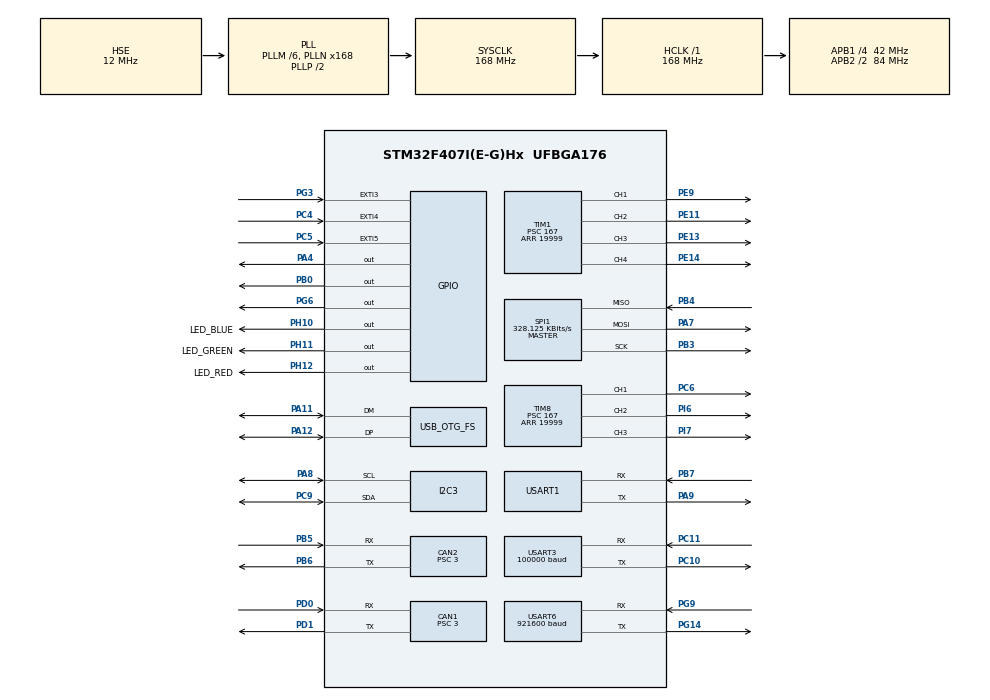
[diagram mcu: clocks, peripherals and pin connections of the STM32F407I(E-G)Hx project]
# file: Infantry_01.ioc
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CAN1.ABOM=ENABLE
CAN1.BS1=CAN_BS1_10TQ
CAN1.BS2=CAN_BS2_3TQ
CAN1.CalculateBaudRate=1000000
CAN1.CalculateTimeBit=1000
CAN1.CalculateTimeQuantum=71.42857142857143
CAN1.Prescaler=3
CAN2.ABOM=ENABLE
CAN2.BS1=CAN_BS1_10TQ
CAN2.BS2=CAN_BS2_3TQ
CAN2.CalculateBaudRate=1000000
CAN2.CalculateTimeBit=1000
CAN2.CalculateTimeQuantum=71.42857142857143
CAN2.Prescaler=3
Dma.Request0=USART1_RX
Dma.Request1=USART1_TX
Dma.Request2=USART3_RX
Dma.Request3=SPI1_RX
Dma.Request4=SPI1_TX
Dma.Request5=USART6_RX
Dma.SPI1_RX.3.Direction=DMA_PERIPH_TO_MEMORY
Dma.SPI1_RX.3.FIFOMode=DMA_FIFOMODE_DISABLE
Dma.SPI1_RX.3.Instance=DMA2_Stream0
Dma.SPI1_RX.3.MemDataAlignment=DMA_MDATAALIGN_BYTE
Dma.SPI1_RX.3.MemInc=DMA_MINC_ENABLE
Dma.SPI1_RX.3.Mode=DMA_NORMAL
Dma.SPI1_RX.3.PeriphDataAlignment=DMA_PDATAALIGN_BYTE
Dma.SPI1_RX.3.PeriphInc=DMA_PINC_DISABLE
Dma.SPI1_RX.3.Priority=DMA_PRIORITY_LOW
Dma.SPI1_TX.4.Direction=DMA_MEMORY_TO_PERIPH
Dma.SPI1_TX.4.FIFOMode=DMA_FIFOMODE_DISABLE
Dma.SPI1_TX.4.Instance=DMA2_Stream3
Dma.SPI1_TX.4.MemDataAlignment=DMA_MDATAALIGN_BYTE
Dma.SPI1_TX.4.MemInc=DMA_MINC_ENABLE
Dma.SPI1_TX.4.Mode=DMA_NORMAL
Dma.SPI1_TX.4.PeriphDataAlignment=DMA_PDATAALIGN_BYTE
Dma.SPI1_TX.4.PeriphInc=DMA_PINC_DISABLE
Dma.SPI1_TX.4.Priority=DMA_PRIORITY_LOW
Dma.USART1_RX.0.Direction=DMA_PERIPH_TO_MEMORY
Dma.USART1_RX.0.FIFOMode=DMA_FIFOMODE_DISABLE
Dma.USART1_RX.0.Instance=DMA2_Stream2
Dma.USART1_RX.0.MemDataAlignment=DMA_MDATAALIGN_BYTE
Dma.USART1_RX.0.MemInc=DMA_MINC_ENABLE
Dma.USART1_RX.0.Mode=DMA_NORMAL
Dma.USART1_RX.0.PeriphDataAlignment=DMA_PDATAALIGN_BYTE
Dma.USART1_RX.0.PeriphInc=DMA_PINC_DISABLE
Dma.USART1_RX.0.Priority=DMA_PRIORITY_VERY_HIGH
Dma.USART1_TX.1.Direction=DMA_MEMORY_TO_PERIPH
Dma.USART1_TX.1.FIFOMode=DMA_FIFOMODE_DISABLE
Dma.USART1_TX.1.Instance=DMA2_Stream7
Dma.USART1_TX.1.MemDataAlignment=DMA_MDATAALIGN_BYTE
Dma.USART1_TX.1.MemInc=DMA_MINC_ENABLE
Dma.USART1_TX.1.Mode=DMA_NORMAL
Dma.USART1_TX.1.PeriphDataAlignment=DMA_PDATAALIGN_BYTE
Dma.USART1_TX.1.PeriphInc=DMA_PINC_DISABLE
Dma.USART1_TX.1.Priority=DMA_PRIORITY_VERY_HIGH
Dma.USART3_RX.2.Direction=DMA_PERIPH_TO_MEMORY
Dma.USART3_RX.2.FIFOMode=DMA_FIFOMODE_DISABLE
Dma.USART3_RX.2.Instance=DMA1_Stream1
Dma.USART3_RX.2.MemDataAlignment=DMA_MDATAALIGN_BYTE
Dma.USART3_RX.2.MemInc=DMA_MINC_ENABLE
Dma.USART3_RX.2.Mode=DMA_CIRCULAR
Dma.USART3_RX.2.PeriphDataAlignment=DMA_PDATAALIGN_BYTE
Dma.USART3_RX.2.PeriphInc=DMA_PINC_DISABLE
Dma.USART3_RX.2.Priority=DMA_PRIORITY_VERY_HIGH
Dma.USART6_RX.5.Direction=DMA_PERIPH_TO_MEMORY
Dma.USART6_RX.5.FIFOMode=DMA_FIFOMODE_DISABLE
Dma.USART6_RX.5.Instance=DMA2_Stream1
Dma.USART6_RX.5.MemDataAlignment=DMA_MDATAALIGN_BYTE
Dma.USART6_RX.5.MemInc=DMA_MINC_ENABLE
Dma.USART6_RX.5.Mode=DMA_CIRCULAR
Dma.USART6_RX.5.PeriphDataAlignment=DMA_PDATAALIGN_BYTE
Dma.USART6_RX.5.PeriphInc=DMA_PINC_DISABLE
Dma.USART6_RX.5.Priority=DMA_PRIORITY_VERY_HIGH
FREERTOS.Tasks01=defaultTask,0,128,StartDefaultTask,Default,NULL,Dynamic,NULL,NULL;sensor_task,2,128,sensor_task_func,As external,NULL,Dynamic,NULL,NULL;motor_task,3,256,motor_task_func,As external,NULL,Dynamic,NULL,NULL;gimbal_task,1,512,gimbal_task_func,As external,NULL,Dynamic,NULL,NULL;chassis_task,1,512,chassis_task_func,As external,NULL,Dynamic,NULL,NULL;recv_cmd_task,-1,512,recv_cmd_task_func,As external,NULL,Dynamic,NULL,NULL;shoot_task,1,512,shoot_task_func,As external,NULL,Dynamic,NULL,NULL;send_info_task,3,512,send_info_task_func,As external,NULL,Dynamic,NULL,NULL
I2C3.I2C_Mode=I2C_Fast
Mcu.Family=STM32F4
Mcu.Name=STM32F407I(E-G)Hx
Mcu.Package=UFBGA176
NVIC.CAN1_RX0_IRQn=true\:5\:0\:false\:false\:true\:true\:true\:true\:true
NVIC.CAN2_RX0_IRQn=true\:5\:0\:false\:false\:true\:true\:true\:true\:true
NVIC.DMA1_Stream1_IRQn=true\:5\:0\:false\:false\:true\:true\:false\:true\:true
NVIC.DMA2_Stream0_IRQn=true\:5\:0\:false\:false\:true\:true\:false\:true\:true
NVIC.DMA2_Stream1_IRQn=true\:5\:0\:false\:false\:true\:true\:false\:true\:true
NVIC.DMA2_Stream2_IRQn=true\:5\:0\:false\:false\:true\:true\:false\:true\:true
NVIC.DMA2_Stream3_IRQn=true\:5\:0\:false\:false\:true\:true\:false\:true\:true
NVIC.DMA2_Stream7_IRQn=true\:5\:0\:false\:false\:true\:true\:false\:true\:true
NVIC.OTG_FS_IRQn=true\:5\:0\:false\:false\:true\:true\:true\:true\:true
NVIC.PriorityGroup=NVIC_PRIORITYGROUP_4
NVIC.TIM2_IRQn=true\:15\:0\:false\:false\:true\:false\:false\:true\:true
NVIC.TimeBase=TIM2_IRQn
NVIC.TimeBaseIP=TIM2
NVIC.USART1_IRQn=true\:5\:0\:false\:false\:true\:true\:true\:true\:true
NVIC.USART3_IRQn=true\:5\:0\:false\:false\:false\:true\:true\:true\:true
NVIC.USART6_IRQn=true\:5\:0\:false\:false\:false\:true\:true\:true\:true
PA11.Mode=Device_Only
PA11.Signal=USB_OTG_FS_DM
PA12.Mode=Device_Only
PA12.Signal=USB_OTG_FS_DP
PA13.Mode=Serial_Wire
PA13.Signal=SYS_JTMS-SWDIO
PA14.Mode=Serial_Wire
PA14.Signal=SYS_JTCK-SWCLK
PA4.Signal=GPIO_Output
PA7.Mode=Full_Duplex_Master
PA7.Signal=SPI1_MOSI
PA8.Mode=I2C
PA8.Signal=I2C3_SCL
PA9.Mode=Asynchronous
PA9.Signal=USART1_TX
PB0.Signal=GPIO_Output
PB3.Mode=Full_Duplex_Master
PB3.Signal=SPI1_SCK
PB4.Mode=Full_Duplex_Master
PB4.Signal=SPI1_MISO
PB5.Mode=CAN_Activate
PB5.Signal=CAN2_RX
PB6.Mode=CAN_Activate
PB6.Signal=CAN2_TX
PB7.Mode=Asynchronous
PB7.Signal=USART1_RX
PC10.Mode=Asynchronous
PC10.Signal=USART3_TX
PC11.Mode=Asynchronous
PC11.Signal=USART3_RX
PC14-OSC32_IN.Mode=LSE-External-Oscillator
PC14-OSC32_IN.Signal=RCC_OSC32_IN
PC15-OSC32_OUT.Mode=LSE-External-Oscillator
PC15-OSC32_OUT.Signal=RCC_OSC32_OUT
PC4.Signal=GPXTI4
PC5.Signal=GPXTI5
PC6.Signal=S_TIM8_CH1
PC9.Mode=I2C
PC9.Signal=I2C3_SDA
PD0.Mode=CAN_Activate
PD0.Signal=CAN1_RX
PD1.Mode=CAN_Activate
PD1.Signal=CAN1_TX
PE11.Signal=S_TIM1_CH2
PE13.Signal=S_TIM1_CH3
PE14.Signal=S_TIM1_CH4
PE9.Signal=S_TIM1_CH1
PG14.Mode=Asynchronous
PG14.Signal=USART6_TX
PG3.Signal=GPXTI3
PG6.Signal=GPIO_Output
PG9.Mode=Asynchronous
PG9.Signal=USART6_RX
PH0-OSC_IN.Mode=HSE-External-Oscillator
PH0-OSC_IN.Signal=RCC_OSC_IN
PH1-OSC_OUT.Mode=HSE-External-Oscillator
PH1-OSC_OUT.Signal=RCC_OSC_OUT
PH10.GPIO_Label=LED_BLUE
PH10.Signal=GPIO_Output
PH11.GPIO_Label=LED_GREEN
PH11.Signal=GPIO_Output
PH12.GPIO_Label=LED_RED
PH12.Signal=GPIO_Output
PI6.Signal=S_TIM8_CH2
PI7.Signal=S_TIM8_CH3
ProjectManager.HeapSize=0x1000
ProjectManager.StackSize=0x400
ProjectManager.TargetToolchain=CMake
RCC.48MHZClocksFreq_Value=48000000
RCC.AHBFreq_Value=168000000
RCC.APB1CLKDivider=RCC_HCLK_DIV4
RCC.APB1Freq_Value=42000000
RCC.APB1TimFreq_Value=84000000
RCC.APB2CLKDivider=RCC_HCLK_DIV2
RCC.APB2Freq_Value=84000000
RCC.APB2TimFreq_Value=168000000
RCC.CortexFreq_Value=168000000
RCC.HCLKFreq_Value=168000000
RCC.HSE_VALUE=12000000
RCC.HSI_VALUE=16000000
RCC.PLLM=6
RCC.PLLN=168
RCC.PLLQ=7
RCC.SYSCLKFreq_VALUE=168000000
RCC.SYSCLKSource=RCC_SYSCLKSOURCE_PLLCLK
RCC.VCOOutputFreq_Value=336000000
SH.S_TIM1_CH1.0=TIM1_CH1,PWM Generation1 CH1
SH.S_TIM1_CH2.0=TIM1_CH2,PWM Generation2 CH2
SH.S_TIM1_CH3.0=TIM1_CH3,PWM Generation3 CH3
SH.S_TIM1_CH4.0=TIM1_CH4,PWM Generation4 CH4
SH.S_TIM8_CH1.0=TIM8_CH1,PWM Generation1 CH1
SH.S_TIM8_CH2.0=TIM8_CH2,PWM Generation2 CH2
SH.S_TIM8_CH3.0=TIM8_CH3,PWM Generation3 CH3
SPI1.BaudRatePrescaler=SPI_BAUDRATEPRESCALER_256
SPI1.CLKPhase=SPI_PHASE_2EDGE
SPI1.CLKPolarity=SPI_POLARITY_HIGH
SPI1.CalculateBaudRate=328.125 KBits/s
SPI1.Direction=SPI_DIRECTION_2LINES
SPI1.Mode=SPI_MODE_MASTER
SPI1.VirtualType=VM_MASTER
TIM1.Channel-PWM\ Generation1\ CH1=TIM_CHANNEL_1
TIM1.Channel-PWM\ Generation2\ CH2=TIM_CHANNEL_2
TIM1.Channel-PWM\ Generation3\ CH3=TIM_CHANNEL_3
TIM1.Channel-PWM\ Generation4\ CH4=TIM_CHANNEL_4
TIM1.Period=19999
TIM1.Prescaler=167
TIM1.Pulse-PWM\ Generation1\ CH1=2000
TIM1.Pulse-PWM\ Generation2\ CH2=2000
TIM1.Pulse-PWM\ Generation3\ CH3=2000
TIM1.Pulse-PWM\ Generation4\ CH4=2000
TIM8.Channel-PWM\ Generation1\ CH1=TIM_CHANNEL_1
TIM8.Channel-PWM\ Generation2\ CH2=TIM_CHANNEL_2
TIM8.Channel-PWM\ Generation3\ CH3=TIM_CHANNEL_3
TIM8.Period=19999
TIM8.Prescaler=167
TIM8.Pulse-PWM\ Generation1\ CH1=2000
TIM8.Pulse-PWM\ Generation2\ CH2=2000
TIM8.Pulse-PWM\ Generation3\ CH3=2000
USART1.VirtualMode=VM_ASYNC
USART3.BaudRate=100000
USART3.Parity=PARITY_NONE
USART3.VirtualMode=VM_ASYNC
USART6.BaudRate=921600
USART6.VirtualMode=VM_ASYNC
USB_DEVICE.CLASS_NAME_FS=CDC
USB_DEVICE.VirtualMode-CDC_FS=Cdc
USB_DEVICE.VirtualModeFS=Cdc_FS
USB_OTG_FS.VirtualMode=Device_Only
VP_FREERTOS_VS_CMSIS_V1.Mode=CMSIS_V1
VP_SYS_VS_tim2.Mode=TIM2
VP_TIM1_VS_ClockSourceINT.Mode=Internal
VP_TIM8_VS_ClockSourceINT.Mode=Internal
VP_USB_DEVICE_VS_USB_DEVICE_CDC_FS.Mode=CDC_FS
board=custom

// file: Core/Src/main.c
/* USER CODE BEGIN Header */
/**
  ******************************************************************************
  * @file           : main.c
  * @brief          : Main program body
  ******************************************************************************
  * @attention
  *
  * Copyright (c) 2025 STMicroelectronics.
  * All rights reserved.
  *
  * This software is licensed under terms that can be found in the LICENSE file
  * in the root directory of this software component.
  * If no LICENSE file comes with this software, it is provided AS-IS.
  *
  ******************************************************************************
  */
/* USER CODE END Header */
#include "main.h"
#include "cmsis_os.h"
#include "can.h"
#include "dma.h"
#include "i2c.h"
#include "spi.h"
#include "tim.h"
#include "usart.h"
#include "usb_device.h"
#include "gpio.h"

/* USER CODE BEGIN Includes */

#include "../../Bsp/can/bsp_can.h"

#include "../../Components/remote/remote.h"

#include "../../Application/global_info.h"
/* USER CODE END Includes */

void SystemClock_Config(void);
void MX_FREERTOS_Init(void);

int main(void)
{

  /* MCU Configuration--------------------------------------------------------*/

  /* Reset of all peripherals, Initializes the Flash interface and the Systick. */
  HAL_Init();

  /* Configure the system clock */
  SystemClock_Config();

  /* Initialize all configured peripherals */
  MX_GPIO_Init();
  MX_DMA_Init();
  MX_CAN1_Init();
  MX_CAN2_Init();
  MX_USART1_UART_Init();
  MX_USART3_UART_Init();
  MX_TIM1_Init();
  MX_TIM8_Init();
  MX_SPI1_Init();
  MX_I2C3_Init();
  MX_USART6_UART_Init();
  /* USER CODE BEGIN 2 */

  bsp_can_init();
  Robot_Global_Init();
  /* USER CODE END 2 */

  /* Call init function for freertos objects (in cmsis_os2.c) */
  MX_FREERTOS_Init();

  /* Start scheduler */
  osKernelStart();

  /* We should never get here as control is now taken by the scheduler */

  /* Infinite loop */
  while (1)
  {

  }
}

void SystemClock_Config(void)
{
  RCC_OscInitTypeDef RCC_OscInitStruct = {0};
  RCC_ClkInitTypeDef RCC_ClkInitStruct = {0};

  /** Configure the main internal regulator output voltage
  */
  __HAL_RCC_PWR_CLK_ENABLE();
  __HAL_PWR_VOLTAGESCALING_CONFIG(PWR_REGULATOR_VOLTAGE_SCALE1);

  /** Initializes the RCC Oscillators according to the specified parameters
  * in the RCC_OscInitTypeDef structure.
  */
  RCC_OscInitStruct.OscillatorType = RCC_OSCILLATORTYPE_HSE;
  RCC_OscInitStruct.HSEState = RCC_HSE_ON;
  RCC_OscInitStruct.PLL.PLLState = RCC_PLL_ON;
  RCC_OscInitStruct.PLL.PLLSource = RCC_PLLSOURCE_HSE;
  RCC_OscInitStruct.PLL.PLLM = 6;
  RCC_OscInitStruct.PLL.PLLN = 168;
  RCC_OscInitStruct.PLL.PLLP = RCC_PLLP_DIV2;
  RCC_OscInitStruct.PLL.PLLQ = 7;
  if (HAL_RCC_OscConfig(&RCC_OscInitStruct) != HAL_OK)
  {
    Error_Handler();
  }

  /** Initializes the CPU, AHB and APB buses clocks
  */
  RCC_ClkInitStruct.ClockType = RCC_CLOCKTYPE_HCLK|RCC_CLOCKTYPE_SYSCLK
                              |RCC_CLOCKTYPE_PCLK1|RCC_CLOCKTYPE_PCLK2;
  RCC_ClkInitStruct.SYSCLKSource = RCC_SYSCLKSOURCE_PLLCLK;
  RCC_ClkInitStruct.AHBCLKDivider = RCC_SYSCLK_DIV1;
  RCC_ClkInitStruct.APB1CLKDivider = RCC_HCLK_DIV4;
  RCC_ClkInitStruct.APB2CLKDivider = RCC_HCLK_DIV2;

  if (HAL_RCC_ClockConfig(&RCC_ClkInitStruct, FLASH_LATENCY_5) != HAL_OK)
  {
    Error_Handler();
  }
}

void HAL_TIM_PeriodElapsedCallback(TIM_HandleTypeDef *htim)
{
  if (htim->Instance == TIM2)
  {
    HAL_IncTick();
  }
}

void Error_Handler(void)
{
  __disable_irq();
  while (1)
  {
  }
}

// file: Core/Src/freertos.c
/* USER CODE BEGIN Header */
/**
  ******************************************************************************
  * File Name          : freertos.c
  * Description        : Code for freertos applications
  ******************************************************************************
  * @attention
  *
  * Copyright (c) 2025 STMicroelectronics.
  * All rights reserved.
  *
  * This software is licensed under terms that can be found in the LICENSE file
  * in the root directory of this software component.
  * If no LICENSE file comes with this software, it is provided AS-IS.
  *
  ******************************************************************************
  */
/* USER CODE END Header */

#include "FreeRTOS.h"
#include "task.h"
#include "main.h"
#include "cmsis_os.h"

osThreadId defaultTaskHandle;
osThreadId sensor_taskHandle;
osThreadId motor_taskHandle;
osThreadId gimbal_taskHandle;
osThreadId chassis_taskHandle;
osThreadId recv_cmd_taskHandle;
osThreadId shoot_taskHandle;
osThreadId send_info_taskHandle;

void StartDefaultTask(void const * argument);
extern void sensor_task_func(void const * argument);
extern void motor_task_func(void const * argument);
extern void gimbal_task_func(void const * argument);
extern void chassis_task_func(void const * argument);
extern void recv_cmd_task_func(void const * argument);
extern void shoot_task_func(void const * argument);
extern void send_info_task_func(void const * argument);

extern void MX_USB_DEVICE_Init(void);
void MX_FREERTOS_Init(void); /* (MISRA C 2004 rule 8.1) */

/* GetIdleTaskMemory prototype (linked to static allocation support) */
void vApplicationGetIdleTaskMemory( StaticTask_t **ppxIdleTaskTCBBuffer, StackType_t **ppxIdleTaskStackBuffer, uint32_t *pulIdleTaskStackSize );

/* USER CODE BEGIN GET_IDLE_TASK_MEMORY */
static StaticTask_t xIdleTaskTCBBuffer;
static StackType_t xIdleStack[configMINIMAL_STACK_SIZE];

void vApplicationGetIdleTaskMemory( StaticTask_t **ppxIdleTaskTCBBuffer, StackType_t **ppxIdleTaskStackBuffer, uint32_t *pulIdleTaskStackSize )
{
  *ppxIdleTaskTCBBuffer = &xIdleTaskTCBBuffer;
  *ppxIdleTaskStackBuffer = &xIdleStack[0];
  *pulIdleTaskStackSize = configMINIMAL_STACK_SIZE;
  /* place for user code */
}
/* USER CODE END GET_IDLE_TASK_MEMORY */

void MX_FREERTOS_Init(void) {

  /* Create the thread(s) */
  /* definition and creation of defaultTask */
  osThreadDef(defaultTask, StartDefaultTask, osPriorityNormal, 0, 128);
  defaultTaskHandle = osThreadCreate(osThread(defaultTask), NULL);

  /* definition and creation of sensor_task */
  osThreadDef(sensor_task, sensor_task_func, osPriorityHigh, 0, 128);
  sensor_taskHandle = osThreadCreate(osThread(sensor_task), NULL);

  /* definition and creation of motor_task */
  osThreadDef(motor_task, motor_task_func, osPriorityRealtime, 0, 256);
  motor_taskHandle = osThreadCreate(osThread(motor_task), NULL);

  /* definition and creation of gimbal_task */
  osThreadDef(gimbal_task, gimbal_task_func, osPriorityAboveNormal, 0, 512);
  gimbal_taskHandle = osThreadCreate(osThread(gimbal_task), NULL);

  /* definition and creation of chassis_task */
  osThreadDef(chassis_task, chassis_task_func, osPriorityAboveNormal, 0, 512);
  chassis_taskHandle = osThreadCreate(osThread(chassis_task), NULL);

  /* definition and creation of recv_cmd_task */
  osThreadDef(recv_cmd_task, recv_cmd_task_func, osPriorityBelowNormal, 0, 512);
  recv_cmd_taskHandle = osThreadCreate(osThread(recv_cmd_task), NULL);

  /* definition and creation of shoot_task */
  osThreadDef(shoot_task, shoot_task_func, osPriorityAboveNormal, 0, 512);
  shoot_taskHandle = osThreadCreate(osThread(shoot_task), NULL);

  /* definition and creation of send_info_task */
  osThreadDef(send_info_task, send_info_task_func, osPriorityRealtime, 0, 512);
  send_info_taskHandle = osThreadCreate(osThread(send_info_task), NULL);

}

void StartDefaultTask(void const * argument)
{
  /* init code for USB_DEVICE */
  MX_USB_DEVICE_Init();
  for(;;)
  {
    osDelay(1);
  }
}
